# ATmega128 register map
Vendor: Atmel; File version: 1.0
CPU: other r0p0, little endian, no MPU, no FPU, 4 interrupt priority bits
Registers are 8-bit, read-write, reset 0x0 unless marked. A register's access mark holds for its fields unless they carry their own. Offsets are from the block's base; [hi:lo] are bit positions; {n}, {i} and the like mark numbered series; 'fields as' and 'values as' point back to an identical list.

## BOOT_LOAD — Bootloader
Base 0x00800068
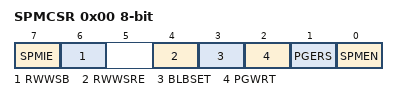
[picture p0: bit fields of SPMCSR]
0x00 SPMCSR — Store Program Memory Control Register
  [7] SPMIE — SPM Interrupt Enable
  [6] RWWSB — Read While Write Section Busy
  [4] RWWSRE — Read While Write section read enable
  [3] BLBSET — Boot Lock Bit Set
  [2] PGWRT — Page Write
  [1] PGERS — Page Erase
  [0] SPMEN — Store Program Memory Enable

## CPU — CPU Registers
Base 0x00800054
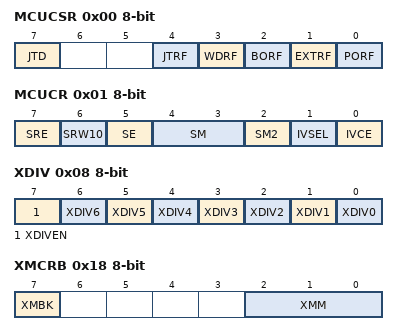
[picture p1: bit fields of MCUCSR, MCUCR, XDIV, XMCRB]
0x00 MCUCSR — MCU Control And Status Register
  [7] JTD — JTAG Interface Disable
  [4] JTRF — JTAG Reset Flag
  [3] WDRF — Watchdog Reset Flag
  [2] BORF — Brown-out Reset Flag
  [1] EXTRF — External Reset Flag
  [0] PORF — Power-on reset flag
0x01 MCUCR — MCU Control Register
  [7] SRE — External SRAM Enable
  [6] SRW10 — External SRAM Wait State Select
  [5] SE — Sleep Enable
  [4:3] SM — Sleep Mode Select
  [2] SM2 — Sleep Mode Select
    0=IDLE
  [1] IVSEL — Interrupt Vector Select
  [0] IVCE — Interrupt Vector Change Enable
0x07 RAMPZ — RAM Page Z Select Register
  [0] RAMPZ0 — RAM Page Z Select Register Bit 0
0x08 XDIV — XTAL Divide Control Register
  [7] XDIVEN — XTAL Divide Enable
  [n] XDIV{n} (n=0..6) — XTAL Divide Select Bit {n}
0x18 XMCRB — External Memory Control Register B
  [7] XMBK — External Memory Bus Keeper Enable
  [2:0] XMM — External Memory High Mask
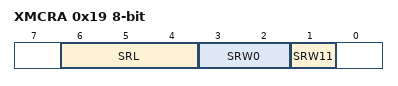
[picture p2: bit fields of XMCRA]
0x19 XMCRA — External Memory Control Register A
  [6:4] SRL — Wait state page limit
    0=LS_N_A_US_0X1100_0XFFFF; 1=LS_0X1100_0X1FFF_US_0X2000_0XFFFF; 2=LS_0X1100_0X3FFF_US_0X4000_0XFFFF; 3=LS_0X1100_0X5FFF_US_0X6000_0XFFFF; 4=LS_0X1100_0X7FFF_US_0X8000_0XFFFF; 5=LS_0X1100_0X9FFF_US_0XA000_0XFFFF; 6=LS_0X1100_0XBFFF_US_0XC000_0XFFFF; 7=LS_0X1100_0XDFFF_US_0XE000_0XFFFF
  [3:2] SRW0 — Wait state select bit lower page
    0=NO_WAIT_STATES; 1=WAIT_ONE_CYCLE_DURING_READ_WRITE_STROBE; 2=WAIT_TWO_CYCLES_DURING_READ_WRITE_STROBE; 3=WAIT_TWO_CYCLES_DURING_READ_WRITE_AND_WAIT_ONE_CYCLE_BEFORE_DRIVING_OUT_NEW_ADDRESS
  [1] SRW11 — Wait state select bit upper page
0x1B OSCCAL — Oscillator Calibration Value
  [7:0] OSCCAL — Oscillator Calibration

## EEPROM
Base 0x0080003C
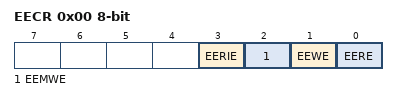
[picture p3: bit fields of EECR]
0x00 EECR — EEPROM Control Register
  [3] EERIE — EEPROM Ready Interrupt Enable
  [2] EEMWE — EEPROM Master Write Enable
  [1] EEWE — EEPROM Write Enable
  [0] EERE — EEPROM Read Enable
0x01 EEDR — EEPROM Data Register
0x02 EEAR 16-bit (reset mask 0xFF) — EEPROM Read/Write Access Bytes

## EXINT — External Interrupts
Base 0x00800058
0x00 EIFR — External Interrupt Flag Register (read-only for debugger)
  [7:0] INTF — External Interrupt Flags
0x01 EIMSK — External Interrupt Mask Register
  [7:0] INT — External Interrupt Request 7 Enable
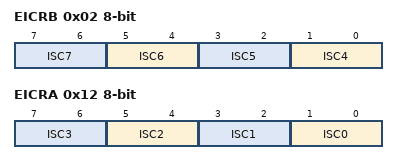
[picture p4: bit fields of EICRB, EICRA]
0x02 EICRB — External Interrupt Control Register B
  [all] fields
    0=LOW_LEVEL_OF_INTX; 1=ANY_LOGICAL_CHANGE_OF_INTX; 2=FALLING_EDGE_OF_INTX; 3=RISING_EDGE_OF_INTX
  [2n-7:2n-8] ISC{n} (n=4..7) — External Interrupt 7-4 Sense Control Bit
0x12 EICRA — External Interrupt Control Register A
  [all] fields
    values as the fields of EICRB
  [2n+1:2n] ISC{n} (n=0..3) — External Interrupt Sense Control Bit

## JTAG — JTAG Interface
Base 0x00800042
0x00 OCDR — On-Chip Debug Related Register in I/O Memory (write-only for debugger)
  [7:0] OCDR — On-Chip Debug Register Bits
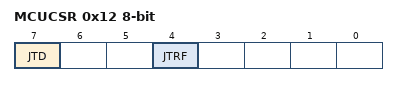
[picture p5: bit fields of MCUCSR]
0x12 MCUCSR — MCU Control And Status Register
  [7] JTD — JTAG Interface Disable
  [4] JTRF — JTAG Reset Flag

## LOCKBIT — Lockbits
Base 0x00800000
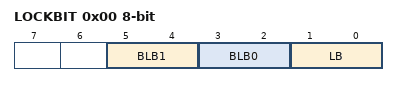
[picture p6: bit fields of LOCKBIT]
0x00 LOCKBIT
  [5:4] BLB1 — Boot Loader Protection Mode
    0=LPM_SPM_DISABLE (LPM and SPM prohibited in Boot Section); 1=LPM_DISABLE (LPM prohibited in Boot Section); 2=SPM_DISABLE (SPM prohibited in Boot Section); 3=NO_LOCK (No lock on SPM and LPM in Boot Section)
  [3:2] BLB0 — Boot Loader Protection Mode
    0=LPM_SPM_DISABLE (LPM and SPM prohibited in Application Section); 1=LPM_DISABLE (LPM prohibited in Application Section); 2=SPM_DISABLE (SPM prohibited in Application Section); 3=NO_LOCK (No lock on SPM and LPM in Application Section)
  [1:0] LB — Memory Lock
    0=PROG_VER_DISABLED (Further programming and verification disabled); 2=PROG_DISABLED (Further programming disabled); 3=NO_LOCK (No memory lock features enabled)
